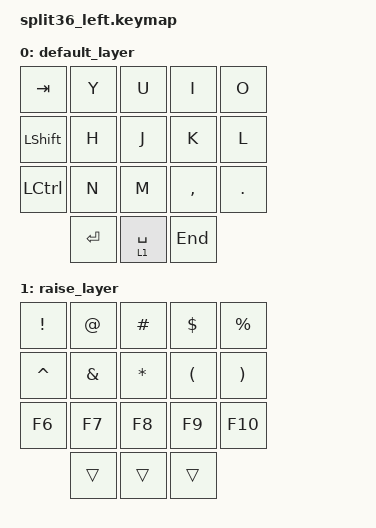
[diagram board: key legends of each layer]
keymap {
  compatible = "zmk,keymap";

  default_layer {
    bindings =
      &kp TAB &kp Y &kp U &kp I &kp O
      &kp LSHFT &kp H &kp J &kp K &kp L
      &kp LCTRL &kp N &kp M &kp COMMA &kp DOT
      &kp ENTER &lt 1 SPACE &kp END
    >;
  };

  raise_layer {
    bindings =
      &kp EXCL &kp AT &kp HASH &kp DLLR &kp PRCNT
      &kp CARET &kp AMPS &kp STAR &kp LPAR &kp RPAR
      &kp F6 &kp F7 &kp F8 &kp F9 &kp F10
      &trans &trans &trans
    >;
  };
};
